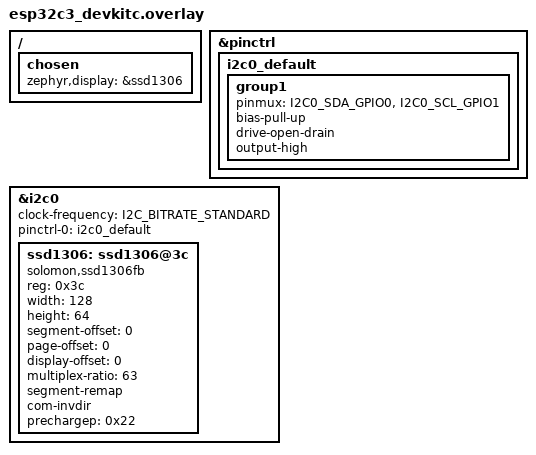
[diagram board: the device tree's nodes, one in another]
/ {
	chosen {
		zephyr,display = &ssd1306;
	};
};

&pinctrl {
	i2c0_default: i2c0_default {
		group1 {
			pinmux = <I2C0_SDA_GPIO0>,
					 <I2C0_SCL_GPIO1>;
			bias-pull-up;
			drive-open-drain;
			output-high;
		};
	};
};

&i2c0 {
	status = "okay";
	clock-frequency = <I2C_BITRATE_STANDARD>;
	pinctrl-0 = <&i2c0_default>;
	pinctrl-names = "default";
	ssd1306: ssd1306@3c {
		compatible = "solomon,ssd1306fb";
		reg = <0x3c>;
		width = <128>;
		height = <64>;
		segment-offset = <0>;
		page-offset = <0>;
		display-offset = <0>;
		multiplex-ratio = <63>;
		segment-remap;
		com-invdir;
		prechargep = <0x22>;
	};
};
